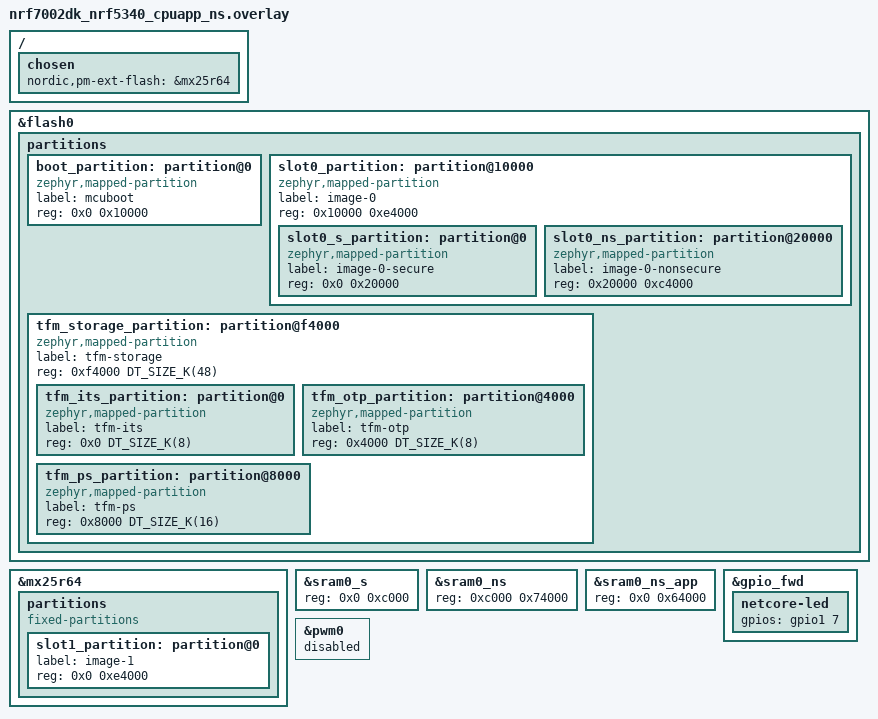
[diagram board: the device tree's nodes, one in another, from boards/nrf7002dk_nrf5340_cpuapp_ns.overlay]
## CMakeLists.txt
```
#
# Cranium firmware: application-core image (TF-M + non-secure application).
#
# Based on the nRF Connect SDK v3.4.0 sample samples/net/aws_iot
# (Copyright (c) 2020 Nordic Semiconductor ASA, LicenseRef-Nordic-5-Clause).
#

cmake_minimum_required(VERSION 3.20.0)

find_package(Zephyr REQUIRED HINTS $ENV{ZEPHYR_BASE})
project(cranium_app)

target_sources(app PRIVATE
  src/main.c
  src/cloud.c
  src/device.c
  src/factory.c
  src/health.c
  src/identity.c
  src/join_policy.c
  src/net.c
  src/ota.c
  src/ota_job.c
  src/store.c
  src/stuck.c
  src/stuck_policy.c
  src/ui.c
  src/version.c
)

target_sources_ifdef(CONFIG_APP_CONSOLE app PRIVATE
  src/console.c
  src/console_cmd.c
  src/console_keys.c
  src/console_parser.c
  src/console_stream.c
)

target_sources_ifdef(CONFIG_APP_BT_OTA app PRIVATE
  src/bt_ota.c
  src/bt_ota_policy.c
)

# MCUmgr's image header needs MCUboot's.
if(CONFIG_APP_BT_OTA)
  target_link_libraries(app PRIVATE MCUBOOT_BOOTUTIL)
endif()

# Only bt_ota.conf turns Bluetooth on. Without the console APP_BT_OTA stays off, which Kconfig only
# warns about, and this would be an image with a Bluetooth host and nobody to read a passkey.
if(CONFIG_BT AND NOT CONFIG_APP_BT_OTA)
  message(FATAL_ERROR "Firmware update over Bluetooth needs the console: CONFIG_APP_CONSOLE is off")
endif()

target_sources_ifndef(CONFIG_APP_CONSOLE app PRIVATE src/log_discard.c)

# The driver's recovery would power the chip back up, so the timer under test would never fire.
target_sources_ifdef(CONFIG_APP_TEST_FAULT_WIFI_DEAD app PRIVATE src/fault_wifi.c)
target_sources_ifdef(CONFIG_APP_BOOT_DIARY app PRIVATE src/boot_diary.c)
if(CONFIG_APP_TEST_FAULT_WIFI_DEAD AND CONFIG_NRF_WIFI_RPU_RECOVERY)
  message(FATAL_ERROR "APP_TEST_FAULT_WIFI_DEAD needs -Dapp_CONFIG_NRF_WIFI_RPU_RECOVERY=n as well")
endif()

zephyr_linker_sources_ifdef(CONFIG_LOG SECTIONS src/log_backend_check.ld)

target_include_directories(app PRIVATE src)
```

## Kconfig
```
#
# Cranium application settings.
#

menu "Cranium application"

config APP_THING_NAME_PREFIX
	string "Prefix of the AWS IoT thing name"
	default "cranium-"
	help
	  The thing name, which is also the MQTT client ID, is this prefix followed by
	  the SoC's factory-programmed device identifier.

config APP_DOWNLOAD_SEC_TAG
	int "TLS security tag for firmware downloads"
	default 202
	help
	  Holds only the root CA used to verify the download server. The device
	  certificate and private key are under CONFIG_MQTT_HELPER_SEC_TAG and are not
	  loaded for downloads.

config APP_SHADOW_INTERVAL_SECONDS
	int "Seconds between heartbeats: the periodic device shadow reports"
	default 30
	range 10 3600
	help
	  The console calls a board online if AWS IoT received one of these within the last
	  90 seconds (ONLINE_WINDOW_MS in cloud/api/src/lib/shadow.mjs). There is no second
	  message for this and no last will: this report is the heartbeat.

config APP_CLOUD_RETRY_SECONDS
	int "Seconds to wait before the first retry of a failed cloud connection"
	default 30
	range 5 600
	help
	  The wait doubles after every failure, up to five minutes.

config APP_WATCHDOG_TIMEOUT_SECONDS
	int "Hardware watchdog timeout"
	default 120
	range 30 600
	help
	  The main event loop feeds the watchdog. If the loop stops, the device resets,
	  and an update that has not been confirmed yet is reverted by the bootloader.

config APP_OTA_REQUIRE_USER_CONSENT
	bool "Wait for a button press before installing an update"
	default n
	help
	  Off: an update that passed every check starts as soon as the board sees the job,
	  with nobody at the board. The signature check, the version check, the trial and
	  the revert hold either way.

	  On, for a product that wants a person to agree: such an update is only offered. It
	  is downloaded and installed after Button 1 is pressed, and refused if Button 2 is
	  pressed. Firmware before 1.7.2 was built this way, and that includes the golden image.

config APP_OTA_SELF_TEST_TIMEOUT_SECONDS
	int "Seconds a new image has to prove itself"
	default 300
	range 60 3600
	help
	  A newly installed image runs on trial. If it has not reconnected to the cloud
	  within this time, the device resets and the bootloader restores the previous
	  image.

config APP_OTA_DOWNLOAD_ATTEMPTS
	int "Download attempts per update before it is reported as failed"
	default 5
	range 1 10
	help
	  The wait before another attempt grows with each one: 10 s, 20 s, 30 s and 40 s
	  with the default, so that an update survives a short outage of the network.

config APP_CONSOLE
	bool "Serial console for setup and debugging"
	depends on SERIAL && LOG
	default y
	select UART_INTERRUPT_DRIVEN
	select RING_BUFFER
	select BASE64
	select SYS_HEAP_RUNTIME_STATS
	help
	  One command per line on uart0: set the device ID, the Wi-Fi network and the
	  cloud settings, load the device credentials, check the status and reset the
	  board, without a host application or a reflash. Log messages come out here as
	  well. For development and provisioning builds only; a release build turns this
	  off with -Dapp_CONFIG_APP_CONSOLE=n, and its log messages then go nowhere. Nothing
	  here can read a secret back out of the device.

if APP_CONSOLE

config APP_CONSOLE_STACK_SIZE
	int "Stack of the console task"
	default 6144
	help
	  Creating the device key and its signing request runs on this stack.

config APP_CONSOLE_THREAD_PRIORITY
	int "Priority of the console task"
	default 12
	help
	  Lower than everything that keeps the product running, and higher than the log
	  thread, so that a reply goes out before the log lines it caused.

config APP_CONSOLE_TX_BUFFER_SIZE
	int "Bytes of output that can wait to be sent"
	default 4096
	range 1024 16384
	help
	  The console task waits for room here. Other threads never do: their line is
	  dropped and counted when it does not fit.

config APP_CONSOLE_LOG_HOLD_SIZE
	int "Bytes of log lines that can wait for a reply to finish"
	default 1024
	range 256 4096
	help
	  They go out all at once, so this cannot be larger than the transmit buffer.

config APP_CONSOLE_RX_BUFFER_SIZE
	int "Bytes of input that can wait for the console task"
	default 512
	range 128 2048

endif # APP_CONSOLE

config APP_BT_OTA
	bool "Firmware update over Bluetooth LE"
	depends on APP_CONSOLE && BT
	help
	  MCUmgr over Bluetooth LE, writing the secondary slot. Off by default. Build with
	  -DSB_EXTRA_CONF_FILE=bt_ota_sysbuild.conf, which also puts the Bluetooth controller on
	  the network core: see firmware/README.md. It needs the console, which is the only way
	  a person can see the passkey.

if APP_BT_OTA

config APP_BT_OTA_WINDOW_SECONDS
	int "Seconds that Button 1 opens Bluetooth for"
	default 120
	range 30 600
	help
	  Advertising stops after this, or as soon as a phone has connected. An authenticated
	  link can run on past it, as long as something happens on it.

config APP_BT_OTA_TRIAL_MIN_SECONDS
	int "Seconds a new image must have run before a person can keep it"
	default 60
	range 30 APP_OTA_SELF_TEST_TIMEOUT_SECONDS
	help
	  An image installed over Bluetooth, on a board that cannot reach Wi-Fi, can be kept by
	  a person at the board: see firmware/README.md. This long first, so that an image that
	  falls over soon after it starts does not get kept, and Wi-Fi has its chance.

endif # APP_BT_OTA

config APP_VERSION_FROM_BUILD
	bool
	default y
	help
	  Take the firmware version from the VERSION file. Off only in host-side tests.

config APP_BOOT_DIARY
	bool "Keep a record of the last boots and send it to the shadow"
	depends on APP_CONSOLE
	default y
	help
	  For finding out over the cloud why a board reset, when nobody can read its serial
	  port. Eight entries: the version, why the boot before it ended, and how far it got.
	  It writes to storage up to four times each boot.

choice APP_TEST_FAULT
	prompt "Fault built into a test image"
	default APP_TEST_FAULT_NONE
	help
	  For testing the way back. An image with a fault is signed and installs like any
	  other, then misbehaves on trial, so the bootloader has to restore the previous
	  image, unless its help says otherwise. Build one with, for example,
	  -Dapp_CONFIG_APP_TEST_FAULT_HANG=y. Never in a release.

config APP_TEST_FAULT_NONE
	bool "No fault"

config APP_TEST_FAULT_NO_CONFIRM
	bool "Runs and reaches the cloud, but never confirms itself"

config APP_TEST_FAULT_HANG
	bool "The main loop hangs, so the watchdog fires"

config APP_TEST_FAULT_CRASH
	bool "A fatal error right after start"

config APP_TEST_FAULT_INIT_POWER_LOSS
	bool "INIT restarts just before it writes the init-complete flag"
	depends on APP_CONSOLE
	help
	  A power cut at the worst moment of first-time setup, for
	  firmware/tests/hil/console_bench.py.

config APP_TEST_FAULT_WIFI_DEAD
	bool "A console command stops the Wi-Fi chip's power, once"
	depends on APP_CONSOLE
	help
	  Nothing happens until TEST_WIFI_DEAD is sent, so this image passes its trial and is
	  confirmed like any other. The command drives BUCKEN low and leaves IOVDD on, and from
	  then on the chip answers nothing. A restart brings it back. Build it with
	  -Dapp_CONFIG_NRF_WIFI_RPU_RECOVERY=n as well, or the driver powers the chip up again
	  and the timers in src/stuck.c never fire. For the chip-dead scenario of
	  firmware/tests/hil/ota_bench.py.

	  With APP_TEST_WIFI_DEAD_AFTER_SECONDS it also fires by itself, for a board with no
	  console: chip-dead-cloud in the same file.

config APP_TEST_FAULT_WRECK_SLOTS
	bool "Damages both image slots and restarts"
	help
	  Clears a word of the primary slot's hash and the first word of the secondary slot,
	  as a compromised application could. MCUboot then has no valid image, and the golden
	  image is the way back, for firmware/tests/hil/golden_bench.py.

config APP_TEST_FAULT_GOLDEN_FLIP
	bool "Damages the golden image in external flash, and runs on"
	help
	  Clears one bit of the golden copy at APP_TEST_GOLDEN_FLIP_OFFSET, through the flash
	  device, since this application's flash map has no area for it. A restore has to refuse
	  it whether the bit is in the image or in its signature, for
	  firmware/tests/hil/golden_bench.py.

endchoice

config APP_TEST_WIFI_DEAD_AFTER_SECONDS
	int "Seconds after its confirmation that the fault fires by itself"
	depends on APP_TEST_FAULT_WIFI_DEAD
	default 0
	range 0 3600
	help
	  0: only TEST_WIFI_DEAD does it. Otherwise it fires this long after the image was
	  confirmed, counted while no update is under way and the cloud is connected, and once
	  per install: the version it fired on is kept in storage, so it does not fire again
	  after the restart it causes. An image that got here with no swap has no trailer, so a
	  revert could not show, and there it does not fire. Build it with KIND set, as in
	  KIND=wifi-dead-auto firmware/tests/hil/build_image.sh, so that its build directory is
	  not the one of the image that waits for the command.

config APP_TEST_GOLDEN_FLIP_OFFSET
	int "Offset in the golden image of the byte that loses a bit"
	depends on APP_TEST_FAULT_GOLDEN_FLIP
	default 0
	range 0 933887
	help
	  `tools/golden.py offsets` gives one in the image's body and one in its signature.

module = APP
module-str = Cranium application
source "subsys/logging/Kconfig.template.log_config"

endmenu

menu "Zephyr Kernel"
source "Kconfig.zephyr"
endmenu
```

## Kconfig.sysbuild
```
#
# Sysbuild configuration: which images are built next to the application.
#

# MCUboot is always part of the build: nothing runs unless it verified the signature.
choice BOOTLOADER
	default BOOTLOADER_MCUBOOT
endchoice

# Without this sysbuild forces the nRF70 Wi-Fi driver off in the application image.
config WIFI_NRF70
	default y

# Flash and RAM layout come from the devicetree overlays in boards/.
config PARTITION_MANAGER
	default n

# The nRF5340 network core runs this project's own image instead of a radio stack.
config SUPPORT_NETCORE_BLINKY
	bool
	default y if SOC_SERIES_NRF53

choice NETCORE

config NETCORE_BLINKY
	bool "Cranium base-function image (LED heartbeat)"
	depends on SUPPORT_NETCORE_BLINKY
	help
	  Build firmware/netcore as the network-core image. It has no radio stack,
	  no keys and no console; it only toggles an LED.

endchoice

config NETCORE_IMAGE_NAME
	default "netcore_blinky" if NETCORE_BLINKY

config NETCORE_IMAGE_PATH
	default "$(APP_DIR)/../netcore" if NETCORE_BLINKY

# Firmware update over Bluetooth LE. Off unless bt_ota_sysbuild.conf is given: see there.
config APP_BT_OTA
	bool "Firmware update over Bluetooth LE"
	help
	  Adds src/bt_ota.c and the Bluetooth host to the application, through bt_ota.conf. The
	  network core has to run the Bluetooth controller, so bt_ota_sysbuild.conf selects that
	  too, and it has to be flashed over the debug port.

source "share/sysbuild/Kconfig"
```

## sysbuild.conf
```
#
# Sysbuild settings shared by every image.
#

SB_CONFIG_BOOTLOADER_MCUBOOT=y
SB_CONFIG_PARTITION_MANAGER=n
SB_CONFIG_WIFI_NRF70=y

# Images are signed with this project's own ECDSA P-256 key. The private key is kept
# outside the repository, in the home directory of whoever builds a release: create it
# with `python tools/keys.py generate` (or obtain the team key). Without this option
# the build would fall back to MCUboot's published debug key, which anyone can sign with.
SB_CONFIG_BOOT_SIGNATURE_TYPE_ECDSA_P256=y
SB_CONFIG_BOOT_SIGNATURE_KEY_FILE="\$ENV{HOME}/.cranium/mcuboot_signing_key.pem"

# Swap with revert: a new image runs once in "test" state and the bootloader puts the
# previous image back unless the application confirms it.
SB_CONFIG_MCUBOOT_MODE_SWAP_USING_MOVE=y

# Network core: base-function image, flashed over SWD only (not part of OTA).
SB_CONFIG_NETCORE_BLINKY=y
```

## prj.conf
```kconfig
#
# Cranium application-core image: settings that do not depend on the board.
# Board specifics (Wi-Fi, TF-M, bootloader, flash) are in boards/.
#
# Based on nRF Connect SDK v3.4.0 samples/net/aws_iot/prj.conf
# (Copyright (c) 2020 Nordic Semiconductor ASA, LicenseRef-Nordic-5-Clause).
#

# Diagnostics
CONFIG_LOG=y
CONFIG_ASSERT=y
CONFIG_REBOOT=y
CONFIG_HW_ID_LIBRARY=y

# Heap and stacks (the board file raises these for Wi-Fi and TLS)
CONFIG_HEAP_MEM_POOL_SIZE=8192
CONFIG_MAIN_STACK_SIZE=4096
CONFIG_SYSTEM_WORKQUEUE_STACK_SIZE=2048

# Network
CONFIG_NETWORKING=y
CONFIG_NET_NATIVE=y
CONFIG_NET_IPV4=y
CONFIG_NET_CONNECTION_MANAGER=y
# The driver's Kconfig sets 16 only along with its recovery, and the default is 5. Named here so that
# a fault image built without the recovery has the same queue as every other image.
CONFIG_NET_MGMT_EVENT_QUEUE_SIZE=16

# AWS IoT. The endpoint and the thing name are provisioned per device at run time and
# kept in secure storage, so no account-specific value is built into the image.
CONFIG_AWS_IOT=y
CONFIG_AWS_IOT_AUTO_DEVICE_SHADOW_REQUEST=n

# MQTT over TLS only (port 8883). Credentials live under this security tag.
CONFIG_MQTT_HELPER=y
CONFIG_MQTT_HELPER_SEC_TAG=201
CONFIG_MQTT_HELPER_STACK_SIZE=4096
CONFIG_MQTT_HELPER_PAYLOAD_BUFFER_LEN=4096
CONFIG_MQTT_HELPER_RX_TX_BUFFER_SIZE=512
CONFIG_MQTT_KEEPALIVE=120
CONFIG_MQTT_CLEAN_SESSION=y
# No last-will message: the device policy in AWS IoT allows publishing to the device's
# own shadow and jobs topics only, and a connection that announces any other topic is
# refused.
CONFIG_MQTT_HELPER_LAST_WILL=n

# Never compile certificates or keys into the firmware. With this option on, the device
# private key would be part of every OTA image stored in the cloud.
CONFIG_MQTT_HELPER_PROVISION_CERTIFICATES=n

# JSON parsing of job documents
CONFIG_CJSON_LIB=y

# Buttons (update confirmation, factory reset) and the hardware watchdog
CONFIG_INPUT=y
CONFIG_WATCHDOG=y

# Firmware download over HTTPS into the secondary slot. The application drives this
# itself instead of using the aws_fota library, which starts downloading without
# asking, reports success before the new image has run, and checks neither the
# version nor a digest.
CONFIG_AWS_FOTA=n
CONFIG_FOTA_DOWNLOAD=y
CONFIG_FOTA_DOWNLOAD_PROGRESS_EVT=y
CONFIG_FOTA_CLIENT_AUTOSCHEDULE_UPDATE=n
CONFIG_FOTA_DOWNLOAD_BUF_SZ=4096
CONFIG_DFU_TARGET=y
CONFIG_DFU_TARGET_MCUBOOT=y
CONFIG_DOWNLOADER=y
CONFIG_DOWNLOADER_STACK_SIZE=4096
# Presigned download URLs are long.
CONFIG_DOWNLOADER_MAX_FILENAME_SIZE=2048
# Never follow a redirect: it could lead to another host or to plain HTTP.
CONFIG_DOWNLOADER_MAX_REDIRECTS=0

# ---------------------------------------------------------------------------------
# Development and provisioning build: the serial console (src/console.h). A release
# build turns it off with -Dapp_CONFIG_APP_CONSOLE=n.
# ---------------------------------------------------------------------------------
CONFIG_APP_CONSOLE=y
# The console owns uart0, and logs go through it. Nothing else may print there. The
# second line overrides what the board's defaults say.
CONFIG_CONSOLE=n
CONFIG_UART_CONSOLE=n

# On-device key generation and certificate signing request
CONFIG_MBEDTLS_X509_CREATE_C=y
CONFIG_MBEDTLS_X509_CSR_WRITE_C=y
CONFIG_PSA_WANT_KEY_TYPE_ECC_KEY_PAIR_GENERATE=y
CONFIG_PSA_WANT_KEY_TYPE_ECC_KEY_PAIR_EXPORT=y
CONFIG_PSA_WANT_KEY_TYPE_ECC_KEY_PAIR_IMPORT=y
```

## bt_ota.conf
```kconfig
#
# What the application core needs for firmware updates over Bluetooth LE. Applied by
# sysbuild.cmake when SB_CONFIG_APP_BT_OTA is on. See bt_ota_sysbuild.conf.
#

CONFIG_APP_BT_OTA=y

# These sizes are not measured on a board yet. See "Before relying on it" in firmware/README.md.
# The Bluetooth stack asks for 4096 bytes more of heap, which CONFIG_HEAP_MEM_POOL_IGNORE_MIN drops
# in this project, and the IPC with the network core takes its queues from there at the first
# press. This keeps what Wi-Fi and TLS have free as it is without Bluetooth.
CONFIG_HEAP_MEM_POOL_SIZE=44240

# One peripheral link and nothing else: no scanning, no central role, no bonds in flash.
CONFIG_BT=y
CONFIG_BT_PERIPHERAL=y
CONFIG_BT_MAX_CONN=1
CONFIG_BT_DEVICE_NAME="Cranium"
CONFIG_BT_GATT_CACHING=n
CONFIG_BT_GATT_SERVICE_CHANGED=n

# On the air only as a resolvable private address, and a new one every 15 minutes. Nothing ever
# gets the key to resolve it, because nothing bonds.
CONFIG_BT_PRIVACY=y

# LE Secure Connections with MITM protection and a full-length key, or no pairing at all.
# A pairing lasts as long as the link: nothing is kept, so no phone can come back later.
CONFIG_BT_SMP=y
CONFIG_BT_SMP_SC_ONLY=y
CONFIG_BT_SMP_APP_PAIRING_ACCEPT=y
CONFIG_BT_BONDABLE=n
CONFIG_BT_SETTINGS=n

# Pairing runs on this thread. The default is for applications that do little, and nothing has
# measured how much this takes on a board yet.
CONFIG_BT_RX_STACK_SIZE=2048

# Room for one SMP packet in one ATT write, as in Zephyr's smp_svr sample.
CONFIG_BT_L2CAP_TX_MTU=498
CONFIG_BT_BUF_ACL_RX_SIZE=502
CONFIG_BT_BUF_ACL_TX_SIZE=502

# MCUmgr, with the image group only: there is no way to reset the board, read a file or run
# a shell from a phone. The permission is the first lock on the characteristic, and the
# hooks in src/bt_ota.c are the second.
CONFIG_NET_BUF=y
CONFIG_ZCBOR=y
CONFIG_CRC=y
CONFIG_MCUMGR=y
CONFIG_MCUMGR_TRANSPORT_BT=y
CONFIG_MCUMGR_TRANSPORT_BT_PERM_RW_AUTHEN=y
CONFIG_MCUMGR_TRANSPORT_NETBUF_SIZE=512
CONFIG_MCUMGR_TRANSPORT_NETBUF_COUNT=4
# As in smp_svr's bt.conf: the upload runs on it, down to the flash driver, and so do the hooks.
CONFIG_MCUMGR_TRANSPORT_WORKQUEUE_STACK_SIZE=4608
CONFIG_MCUMGR_GRP_IMG=y
CONFIG_MCUMGR_GRP_IMG_MUTEX=y
CONFIG_MCUMGR_GRP_IMG_UPLOAD_CHECK_HOOK=y
CONFIG_MCUMGR_GRP_IMG_STATUS_HOOKS=y
CONFIG_MCUMGR_MGMT_NOTIFICATION_HOOKS=y
CONFIG_MCUMGR_SMP_COMMAND_STATUS_HOOKS=y

# Never a permanent swap from a command, which would have no revert.
CONFIG_MCUMGR_GRP_IMG_ALLOW_CONFIRM_NON_ACTIVE_SLOT=n
CONFIG_MCUMGR_GRP_IMG_ALLOW_ERASE_PENDING=n
```

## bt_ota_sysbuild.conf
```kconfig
#
# The one switch for firmware updates over Bluetooth LE. Off in a normal build:
#
#   west build -b nrf7002dk/nrf5340/cpuapp/ns --sysbuild firmware/app -- -DSB_EXTRA_CONF_FILE=bt_ota_sysbuild.conf
#
# See "Firmware update over Bluetooth" in firmware/README.md. It takes a debug-port flash of
# the network core, and only then does an image built with it work.
#

SB_CONFIG_APP_BT_OTA=y

# The network core runs the Bluetooth controller instead of the blinky.
SB_CONFIG_NETCORE_HCI_IPC=y
```

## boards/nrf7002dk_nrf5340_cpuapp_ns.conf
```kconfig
#
# nRF7002 DK, application core, non-secure target (TF-M in the secure domain).
#
# Based on nRF Connect SDK v3.4.0
# samples/net/aws_iot/boards/nrf7002dk_nrf5340_cpuapp_ns.conf
# (Copyright (c) 2023 Nordic Semiconductor ASA, LicenseRef-Nordic-5-Clause).
#

# General
CONFIG_POSIX_TIMERS=y
CONFIG_SYSTEM_WORKQUEUE_STACK_SIZE=4096
CONFIG_HEAP_MEM_POOL_SIZE=40144
CONFIG_NRF_WIFI_CTRL_HEAP_SIZE=20000
CONFIG_NRF_WIFI_DATA_HEAP_SIZE=59856
CONFIG_HEAP_MEM_POOL_IGNORE_MIN=y
CONFIG_HW_STACK_PROTECTION=y
# Device identity: the SoC's factory-programmed 64-bit identifier
CONFIG_HWINFO=y
CONFIG_HW_ID_LIBRARY_SOURCE_DEVICE_ID=y
CONFIG_MAIN_STACK_SIZE=6144

# Optimize the Wi-Fi stack to save memory
CONFIG_NRF70_RX_NUM_BUFS=16
CONFIG_NRF70_MAX_TX_AGGREGATION=4

# Wi-Fi station. Credentials are stored through PSA in TF-M's internal trusted storage.
CONFIG_WIFI=y
CONFIG_WIFI_NRF70=y
CONFIG_WIFI_CREDENTIALS=y
CONFIG_WIFI_NM_WPA_SUPPLICANT=y
CONFIG_FLASH=y
CONFIG_FLASH_PAGE_LAYOUT=y
CONFIG_FLASH_MAP=y

# WEP and WPA (TKIP) are broken. Remove them, and the MD5/RC4 code they need, from
# the supplicant so that they cannot be negotiated at all.
CONFIG_WIFI_NM_WPA_SUPPLICANT_WEP=n
CONFIG_WIFI_NM_WPA_SUPPLICANT_LEGACY_CRYPTO=n

# Sockets
CONFIG_NET_L2_ETHERNET=y
CONFIG_NET_UDP=y
CONFIG_NET_TCP=y
CONFIG_NET_SOCKETS_OFFLOAD=n
CONFIG_NET_DHCPV4=y
CONFIG_NET_CONTEXT_SNDTIMEO=y
CONFIG_NET_CONTEXT_RCVTIMEO=y
CONFIG_NET_RX_STACK_SIZE=2048

# DNS
CONFIG_DNS_RESOLVER=y
CONFIG_NET_SOCKETS_DNS_TIMEOUT=30000

# TLS (Mbed TLS on PSA crypto; the crypto itself runs inside TF-M)
CONFIG_MBEDTLS=y
CONFIG_MBEDTLS_ENABLE_HEAP=y
CONFIG_MBEDTLS_HEAP_SIZE=81920
CONFIG_MBEDTLS_DECLARE_PRIVATE_IDENTIFIERS=y
CONFIG_MBEDTLS_MD_C=y
CONFIG_MBEDTLS_HMAC_DRBG_C=y
CONFIG_MBEDTLS_SHA256_C=y
CONFIG_MBEDTLS_ECP_C=y
CONFIG_MBEDTLS_RSA_C=y
CONFIG_PSA_WANT_KEY_TYPE_RSA_KEY_PAIR_IMPORT=y
CONFIG_PSA_WANT_KEY_TYPE_RSA_KEY_PAIR_EXPORT=y
CONFIG_PSA_WANT_KEY_TYPE_RSA_KEY_PAIR_GENERATE=y
CONFIG_MBEDTLS_SSL_SERVER_NAME_INDICATION=y
# 512-byte MPI limit so that 4096-bit RSA certificate chains can be verified.
CONFIG_MBEDTLS_MPI_MAX_SIZE=512
# ECDHE key agreement and ECDSA are needed for the TLS handshake
CONFIG_PSA_WANT_ALG_ECDH=y
CONFIG_PSA_WANT_ALG_ECDSA=y

CONFIG_NET_SOCKETS_SOCKOPT_TLS=y
# One TLS session for MQTT and one for the HTTPS firmware download, at the same time: the
# connection to AWS IoT stays up during a download, so that a cancellation still arrives.
CONFIG_NET_SOCKETS_TLS_MAX_CONTEXTS=2
# Each session takes its two record buffers from the heap above. What comes in must fit
# 16 KB, because neither S3 nor AWS IoT can be asked to send shorter records. What goes
# out is small: a request for the image, MQTT messages and one client certificate. With
# 16 KB in both directions the second session ran out of heap in the middle of the
# handshake, which Mbed TLS reports as -141 from mbedtls_x509_crt_parse_der().
CONFIG_MBEDTLS_SSL_OUT_CONTENT_LEN=4096

# The device certificate, its private key and the root CA are kept in TF-M Protected
# Storage (encrypted with a key derived from the hardware unique key), not in the image.
CONFIG_TLS_CREDENTIALS_BACKEND_PROTECTED_STORAGE=y

# Connection manager: the application decides when to connect.
CONFIG_L2_WIFI_CONNECTIVITY=y
CONFIG_L2_WIFI_CONNECTIVITY_AUTO_CONNECT=n
CONFIG_L2_WIFI_CONNECTIVITY_AUTO_DOWN=n

# External flash (MX25R64 on SPI) holds the secondary image slot. Use 4 KiB erase
# blocks in the application as well as in the bootloader so that erasing never
# reaches past the end of the slot.
CONFIG_SPI=y
CONFIG_SPI_NOR=y
CONFIG_SPI_NOR_SFDP_DEVICETREE=y
CONFIG_SPI_NOR_FLASH_LAYOUT_PAGE_SIZE=4096

# Bootloader support in the application
CONFIG_BOOTLOADER_MCUBOOT=y
CONFIG_MCUBOOT_USE_ALL_AVAILABLE_RAM=y
CONFIG_MCUBOOT_IMG_MANAGER=y
CONFIG_IMG_MANAGER=y
CONFIG_STREAM_FLASH=y
CONFIG_IMG_ERASE_PROGRESSIVELY=y
# MCUboot is built with downgrade prevention.
CONFIG_MCUBOOT_BOOTLOADER_NO_DOWNGRADE=y

# TF-M
CONFIG_TFM_PROFILE_TYPE_SMALL=y

# Network core: release it from reset. The RTC synchronisation service between the
# cores is not needed because the two images do not talk to each other.
CONFIG_SOC_NRF53_CPUNET_ENABLE=y
CONFIG_NRF53_SYNC_RTC=n

# Link-time optimisation is needed to fit the non-secure image
CONFIG_LTO=y
CONFIG_ISR_TABLES_LOCAL_DECLARATION=y

CONFIG_CBPRINTF_FP_SUPPORT=y
```

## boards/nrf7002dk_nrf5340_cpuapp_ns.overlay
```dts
/*
 * nRF7002 DK application core: flash and RAM layout, external flash, and the pins
 * handed to the network core.
 *
 * Based on nRF Connect SDK v3.4.0
 * samples/net/aws_iot/boards/nrf7002dk_nrf5340_cpuapp_ns.overlay
 * (Copyright (c) 2023 Nordic Semiconductor ASA, LicenseRef-Nordic-5-Clause).
 */

/ {
	chosen {
		/*
		 * Tells the build that the secondary image slot is on external flash.
		 * Needed even though Partition Manager is not used.
		 */
		nordic,pm-ext-flash = &mx25r64;
	};
};

/delete-node/ &boot_partition;
/delete-node/ &slot0_partition;
/delete-node/ &slot1_partition;
/delete-node/ &tfm_its_partition;
/delete-node/ &tfm_otp_partition;
/delete-node/ &tfm_ps_partition;
/delete-node/ &storage_partition;

/*
 * Internal flash (1 MiB):
 *
 *   0x00000  64 KiB   MCUboot (write-protected once it has started the application)
 *   0x10000 912 KiB   primary image slot
 *             128 KiB   TF-M, secure
 *             784 KiB   application, non-secure
 *   0xf4000  48 KiB   TF-M storage: internal trusted storage, NV counters, protected storage
 */
&flash0 {
	partitions {
		boot_partition: partition@0 {
			compatible = "zephyr,mapped-partition";
			label = "mcuboot";
			reg = <0x0 0x10000>;
		};

		slot0_partition: partition@10000 {
			compatible = "zephyr,mapped-partition";
			label = "image-0";
			reg = <0x10000 0xe4000>;
			ranges = <0x0 0x10000 0xe4000>;
			#address-cells = <1>;
			#size-cells = <1>;

			slot0_s_partition: partition@0 {
				compatible = "zephyr,mapped-partition";
				label = "image-0-secure";
				reg = <0x0 0x20000>;
			};

			slot0_ns_partition: partition@20000 {
				compatible = "zephyr,mapped-partition";
				label = "image-0-nonsecure";
				reg = <0x20000 0xc4000>;
			};
		};

		tfm_storage_partition: partition@f4000 {
			compatible = "zephyr,mapped-partition";
			label = "tfm-storage";
			reg = <0xf4000 DT_SIZE_K(48)>;
			ranges = <0x0 0xf4000 DT_SIZE_K(48)>;
			#address-cells = <1>;
			#size-cells = <1>;

			tfm_its_partition: partition@0 {
				compatible = "zephyr,mapped-partition";
				label = "tfm-its";
				reg = <0x0 DT_SIZE_K(8)>;
			};

			tfm_otp_partition: partition@4000 {
				compatible = "zephyr,mapped-partition";
				label = "tfm-otp";
				reg = <0x4000 DT_SIZE_K(8)>;
			};

			tfm_ps_partition: partition@8000 {
				compatible = "zephyr,mapped-partition";
				label = "tfm-ps";
				reg = <0x8000 DT_SIZE_K(16)>;
			};
		};
	};
};

/*
 * External flash: the secondary image slot, the same size as the primary slot.
 *
 * 0x700000 to 0x7e4000 is reserved for the golden image. MCUboot's overlay declares that
 * partition, and this one does not on purpose, so that this application's flash map has no
 * area for it. Keep it out of anything added here. See firmware/README.md.
 */
&mx25r64 {
	status = "okay";

	partitions {
		compatible = "fixed-partitions";
		#address-cells = <1>;
		#size-cells = <1>;

		slot1_partition: partition@0 {
			label = "image-1";
			reg = <0x0 0xe4000>;
		};
	};
};

/*
 * RAM split between the secure and the non-secure domain. TF-M gets 48 KiB at the base
 * of the application-core SRAM; the non-secure window is 0x74000 bytes, of which the
 * top 64 KiB is the memory the two cores can share.
 */
&sram0_s {
	reg = <0x0 0xc000>;
};

&sram0_ns {
	reg = <0xc000 0x74000>;
	ranges = <0x0 0xc000 0x74000>;
};

&sram0_ns_app {
	reg = <0x0 0x64000>;
};

/*
 * Pins owned by the network core. By default the board forwards the network core's
 * UART pins; this image has no console, so only LED2 (P1.07) is handed over. LED1 and
 * both buttons stay with the application core.
 */
&gpio_fwd {
	/delete-node/ uart;

	netcore-led {
		gpios = <&gpio1 7 0>;
	};
};

/* LED1 (P1.06) is driven as a plain GPIO, so release it from the PWM peripheral. */
&pwm0 {
	status = "disabled";
};
```

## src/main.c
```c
/*
 * Cranium firmware, application core: the security domain of the product.
 *
 * This is the non-secure application that runs on top of Trusted Firmware-M. It joins
 * Wi-Fi, keeps an authenticated connection to AWS IoT, reports the device's state and
 * installs firmware updates. Everything is driven by one event loop.
 */

#include <string.h>

#include <cJSON_os.h>
#include <zephyr/kernel.h>
#include <zephyr/logging/log.h>
#include <zephyr/logging/log_ctrl.h>
#include <zephyr/sys/atomic.h>
#include <zephyr/sys/reboot.h>

#include "app_events.h"
#if defined(CONFIG_APP_BT_OTA)
#include "bt_ota.h"
#endif
#include "cloud.h"
#include "console.h"
#include "device.h"
#if defined(CONFIG_APP_TEST_FAULT_WIFI_DEAD)
#include "fault_wifi.h"
#endif
#if defined(CONFIG_APP_BOOT_DIARY)
#include "boot_diary.h"
#endif
#include "identity.h"
#include "factory.h"
#include "health.h"
#include "net.h"
#include "ota.h"
#include "ota_job.h"
#include "stuck.h"
#include "ui.h"
#include "version.h"

#if defined(CONFIG_APP_TEST_FAULT_WRECK_SLOTS)
#include <zephyr/storage/flash_map.h>
#include <zephyr/sys/util.h>
#endif

#if defined(CONFIG_APP_TEST_FAULT_GOLDEN_FLIP)
#include <zephyr/device.h>
#include <zephyr/devicetree.h>
#include <zephyr/drivers/flash.h>
#endif

LOG_MODULE_REGISTER(app, CONFIG_APP_LOG_LEVEL);

#define CLOUD_SETTLE_SECONDS    3
#define CLOUD_BACKOFF_MAX       300

K_MSGQ_DEFINE(event_queue, sizeof(struct app_event), 32, 4);

static int cloud_retry_in = -1;
static int cloud_backoff = CONFIG_APP_CLOUD_RETRY_SECONDS;
/* Since the last report to the shadow. A report that nothing asked for is the board's heartbeat. */
static int seconds_since_report;
/* A tick is in the queue. A main loop that is held up must not come back to a queue full of them. */
static atomic_t tick_queued;

int app_event_post(const struct app_event *event)
{
	return k_msgq_put(&event_queue, event, K_NO_WAIT);
}

int app_event_post_simple(enum app_event_type type)
{
	const struct app_event event = { .type = type };

	return app_event_post(&event);
}

static void on_tick_timer(struct k_timer *timer)
{
	ARG_UNUSED(timer);

	/* Other events are lost if they find the queue full. What counts time goes by uptime. */
	if (atomic_cas(&tick_queued, 0, 1) && app_event_post_simple(APP_EVENT_TICK) != 0) {
		atomic_set(&tick_queued, 0);
	}
}

K_TIMER_DEFINE(tick_timer, on_tick_timer, NULL);

static bool provisioned(void)
{
	return identity_settings_get() != NULL && net_has_credentials();
}

static void update_ui(void)
{
#if defined(CONFIG_APP_BT_OTA)
	if (bt_ota_is_open()) {
		ui_set_state(bt_ota_ui_state());
		return;
	}
#endif

	switch (ota_state()) {
	case OTA_AWAITING_USER:
		ui_set_state(UI_UPDATE_OFFERED);
		return;
	case OTA_RETRY_WAIT:
	case OTA_REFRESHING:
	case OTA_STARTING:
	case OTA_DOWNLOADING:
	case OTA_VERIFYING:
	case OTA_COMMITTING:
	case OTA_REBOOTING:
		ui_set_state(UI_UPDATE_IN_PROGRESS);
		return;
	case OTA_TESTING:
		ui_set_state(UI_UPDATE_TESTING);
		return;
	default:
		break;
	}

	if (device_is_factory()) {
		ui_set_state(UI_FACTORY);
	} else if (!provisioned()) {
		ui_set_state(UI_UNPROVISIONED);
	} else if (!net_is_up()) {
		ui_set_state(UI_NETWORK_CONNECTING);
	} else if (!cloud_is_connected()) {
		ui_set_state(UI_CLOUD_CONNECTING);
	} else {
		ui_set_state(UI_ONLINE);
	}
}

/*
 * Publish what the console shows for this device. Nothing here is secret. AWS IoT stamps the time
 * that it gets the uptime, which is what the console calls the last heartbeat, and there is no other
 * message for that.
 */
static void publish_report(void)
{
	char job[OTA_JOB_ID_MAX + 3] = "null";
	char reported[400];
	const char *job_id = ota_job_id();
	int written;

	if (!cloud_is_connected()) {
		return;
	}

	if (job_id != NULL) {
		(void)snprintk(job, sizeof(job), "\"%s\"", job_id);
	}

	written = snprintk(reported, sizeof(reported),
			   "{\"fw\":{\"version\":\"%s\",\"confirmed\":%s},"
			   "\"ota\":{\"state\":\"%s\",\"job\":%s,\"progress\":%d,"
			   "\"last\":\"%s\",\"error\":\"%s\"},"
			   "\"wifi\":{\"rssi\":%d},\"stuck\":{\"count\":%u,\"reason\":\"%s\"},"
			   "\"uptime\":%lld}",
			   fw_version_running_string(),
			   ota_state() == OTA_TESTING ? "false" : "true", ota_state_name(), job,
			   ota_progress(), ota_last_result(), ota_last_error(), net_rssi(),
			   (unsigned int)stuck_count(), stuck_reason_name(),
			   k_uptime_get() / MSEC_PER_SEC);

	if (written > 0 && written < (int)sizeof(reported)) {
		(void)cloud_shadow_report(reported);
	}

	seconds_since_report = 0;
}

static void on_tick(void)
{
	health_feed();

	/* In factory mode the board stays off the network until INIT has been run. */
	if (!device_is_factory()) {
		net_tick();
	}

	if (net_is_up() && !cloud_is_connected() && identity_settings_get() != NULL) {
		/* The events that set this can be lost. Nobody would try again until the link drops. */
		if (cloud_retry_in < 0 && !cloud_is_connecting()) {
			cloud_retry_in = cloud_backoff;
		}

		if (cloud_retry_in >= 0 && --cloud_retry_in < 0) {
			cloud_connect();
		}
	}

	ota_on_tick();

#if defined(CONFIG_APP_TEST_FAULT_WIFI_DEAD)
	fault_wifi_on_tick();
#endif

#if defined(CONFIG_APP_BT_OTA)
	bt_ota_on_tick();
	update_ui();
#endif

	if (ota_take_changed()) {
		publish_report();
		update_ui();
	} else if (++seconds_since_report >= CONFIG_APP_SHADOW_INTERVAL_SECONDS) {
		publish_report();
	}

	stuck_on_tick();
}

static void on_button(const struct app_event *event)
{
#if defined(CONFIG_APP_BT_OTA)
	if (bt_ota_on_button(event->button.id, event->button.long_press, event->button.physical)) {
		return;
	}
#endif

	/* Holding Button 2 erases everything that was provisioned onto the device. */
	if (event->button.id == APP_BUTTON_2 && event->button.long_press) {
		if (ota_state() != OTA_IDLE) {
			LOG_WRN("Factory reset ignored while an update is in progress");
			return;
		}

		cloud_disconnect();
		(void)factory_reset();
		LOG_PANIC();
		sys_reboot(SYS_REBOOT_COLD);
	}

	ota_on_button(event->button.id);
}

static void on_job_message(void)
{
	enum cloud_job_message kind;
	const char *payload;
	size_t length;

	if (cloud_job_message_get(&kind, &payload, &length)) {
		ota_on_job_message(kind, payload, length);
	}

	if (cloud_job_message_done()) {
		/* Another jobs message arrived meanwhile and was dropped: ask again. */
		(void)cloud_jobs_request_next();
	}
}

static void decide_mode(void)
{
	switch (device_boot()) {
	case DEVICE_BOOT_MIGRATED:
		console_event("CONSOLE", "migrated: device id set to %s", device_id());
		break;
	case DEVICE_BOOT_MIGRATION_FAILED:
		LOG_ERR("The device id could not be stored; will try again at the next boot");
		break;
	case DEVICE_BOOT_UNREADABLE:
		LOG_ERR("Storage could not be read; running as provisioned, nothing was written");
		break;
	default:
		break;
	}
}

static void handle(const struct app_event *event)
{
	switch (event->type) {
	case APP_EVENT_NET_UP:
		LOG_INF("Network is up");
#if defined(CONFIG_APP_BOOT_DIARY)
		boot_diary_stage(BOOT_DIARY_NET_UP);
#endif
		net_report_up();
		cloud_retry_in = CLOUD_SETTLE_SECONDS;
		break;
	case APP_EVENT_NET_DOWN:
		LOG_INF("Network is down");
		net_report_down();
		cloud_disconnect();
		cloud_retry_in = -1;
		break;
	case APP_EVENT_NET_JOIN:
		stuck_on_new_settings();
		(void)net_connect();
		break;
	case APP_EVENT_NET_JOIN_FAILED:
		net_report_join_failed(event->join_failed.reason);
		break;
	case APP_EVENT_CLOUD_UP:
		LOG_INF("Connected to AWS IoT");
		cloud_backoff = CONFIG_APP_CLOUD_RETRY_SECONDS;
		cloud_retry_in = -1;
		ota_on_cloud_up();
		publish_report();
#if defined(CONFIG_APP_BOOT_DIARY)
		boot_diary_stage(BOOT_DIARY_CLOUD_UP);
		boot_diary_report();
#endif
		break;
	case APP_EVENT_CLOUD_DOWN:
		LOG_INF("Disconnected from AWS IoT");
		if (net_is_up()) {
			cloud_retry_in = cloud_backoff;
			cloud_backoff = MIN(cloud_backoff * 2, CLOUD_BACKOFF_MAX);
		}
		break;
	case APP_EVENT_CLOUD_CHANGED:
		stuck_on_new_settings();
		cloud_backoff = CONFIG_APP_CLOUD_RETRY_SECONDS;
		cloud_retry_in = CLOUD_SETTLE_SECONDS;
		break;
	case APP_EVENT_JOB_MESSAGE:
		on_job_message();
		break;
	case APP_EVENT_JOB_ACK:
		ota_on_job_ack(event->job_ack.kind, event->job_ack.sequence, event->job_ack.accepted,
			       event->job_ack.permanent);
		break;
	case APP_EVENT_BUTTON:
		on_button(event);
		break;
	case APP_EVENT_DOWNLOAD:
		ota_on_download(event->download.what, event->download.value);
		break;
	case APP_EVENT_TICK:
		atomic_set(&tick_queued, 0);
		on_tick();
		return;
	case APP_EVENT_CALL:
		event->call.function();
		break;
	default:
		break;
	}

	update_ui();
}

#if defined(CONFIG_APP_TEST_FAULT_WRECK_SLOTS)
/* Where an MCUboot image keeps its metadata. See bootutil/image.h in MCUboot. */
#define IMAGE_HEADER_HDR_SIZE_OFFSET 8
#define IMAGE_TLV_INFO_MAGIC         0x6907
#define IMAGE_TLV_SHA256             0x10

struct image_sizes {
	uint16_t header;
	uint16_t protected_tlv;
	uint32_t image;
};

struct image_tlv_entry {
	uint8_t type;
	uint8_t unused;
	uint16_t length;
};

struct image_tlv_area {
	uint16_t magic;
	uint16_t total;
};

/* Writing zeros needs no erase: that is why anything with write access can do this. */
static void clear_word(const struct flash_area *area, off_t offset)
{
	const uint32_t zero = 0;
	int err = flash_area_write(area, offset, &zero, sizeof(zero));

	LOG_ERR("Test image: cleared the word at %ld of area %u: %d", (long)offset, area->fa_id, err);
}

/* The offset of the first whole word of the image's hash, or -1 if it cannot be found. */
static off_t find_hash(const struct flash_area *area)
{
	struct image_sizes sizes;
	struct image_tlv_area tlvs;
	struct image_tlv_entry entry;
	off_t offset;
	off_t end;

	if (flash_area_read(area, IMAGE_HEADER_HDR_SIZE_OFFSET, &sizes, sizeof(sizes)) != 0) {
		return -1;
	}

	offset = (off_t)sizes.header + sizes.image + sizes.protected_tlv;
	if (flash_area_read(area, offset, &tlvs, sizeof(tlvs)) != 0 ||
	    tlvs.magic != IMAGE_TLV_INFO_MAGIC) {
		return -1;
	}

	end = offset + tlvs.total;
	offset += sizeof(tlvs);

	while (offset < end && flash_area_read(area, offset, &entry, sizeof(entry)) == 0) {
		offset += sizeof(entry);
		if (entry.type == IMAGE_TLV_SHA256) {
			return ROUND_UP(offset, sizeof(uint32_t));
		}
		offset += entry.length;
	}

	return -1;
}

/* What a compromised application could do to the way back. It runs once: then nothing is valid. */
static void wreck_slots(void)
{
	const struct flash_area *area;
	off_t hash;

	if (flash_area_open(PARTITION_ID(slot0_partition), &area) == 0) {
		hash = find_hash(area);
		if (hash >= 0) {
			clear_word(area, hash);
		} else {
			LOG_ERR("Test image: the primary slot's hash was not found");
		}
		flash_area_close(area);
	}

	if (flash_area_open(PARTITION_ID(slot1_partition), &area) == 0) {
		clear_word(area, 0);
		flash_area_close(area);
	}
}
#endif /* CONFIG_APP_TEST_FAULT_WRECK_SLOTS */

#if defined(CONFIG_APP_TEST_FAULT_GOLDEN_FLIP)
/* golden_partition in MCUboot's overlay. This application has no area for it, on purpose. */
#define GOLDEN_FLASH_ADDRESS 0x700000

/* Clear one set bit: writing zeros needs no erase. Each boot of this image clears one more. */
static void damage_golden_copy(void)
{
	const struct device *flash = DEVICE_DT_GET(DT_NODELABEL(mx25r64));
	const off_t address = GOLDEN_FLASH_ADDRESS + CONFIG_APP_TEST_GOLDEN_FLIP_OFFSET;
	uint8_t before;
	uint8_t after;
	int err = device_is_ready(flash) ? flash_read(flash, address, &before, 1) : -ENODEV;

	if (err == 0 && before == 0) {
		LOG_ERR("Test image: the golden byte at %ld has no bit left to clear", (long)address);
		return;
	}

	if (err == 0) {
		after = before & (before - 1);
		err = flash_write(flash, address, &after, 1);
	}

	if (err != 0) {
		LOG_ERR("Test image: the golden copy could not be damaged: %d", err);
		return;
	}

	LOG_ERR("Test image: golden byte at %ld changed from %02x to %02x", (long)address, before,
		after);
}
#endif /* CONFIG_APP_TEST_FAULT_GOLDEN_FLIP */

int main(void)
{
	struct app_event event;

	LOG_INF("Cranium firmware %s", fw_version_running_string());

#if defined(CONFIG_APP_BOOT_DIARY)
	boot_diary_begin();
#endif

	cJSON_Init();

	if (health_init() != 0) {
		LOG_WRN("Running without a watchdog");
	}

	(void)ui_init();

	if (identity_init() != 0) {
		LOG_ERR("Device identity is not available");
	}

	LOG_INF("Thing name: %s", identity_thing_name());

	decide_mode();
	console_start();
	stuck_init();

	if (ota_init() != 0) {
		LOG_ERR("Update manager could not start");
	}

#if defined(CONFIG_APP_BOOT_DIARY)
	boot_diary_stage(BOOT_DIARY_OTA_READY);
#endif

	if (net_init() != 0) {
		LOG_ERR("Networking could not start");
	}

	/*
	 * Whatever came of that. net_init() does not wait for the Wi-Fi stack, so this runs on a chip
	 * that did not come up as well. net_connect() tries the interface again from the tick, and
	 * the stuck timers restart the board if it stays that way.
	 */
	if (cloud_init() != 0) {
		LOG_ERR("The cloud connection could not start");
	}

	if (device_is_factory()) {
		LOG_WRN("Factory mode: send INIT|<id> on the console");
	} else if (net_has_credentials()) {
		(void)net_connect();
	}

	if (!device_is_factory() && !provisioned()) {
		LOG_WRN("This device is not provisioned yet (see tools/provision_device.py)");
	}

	update_ui();
	k_timer_start(&tick_timer, K_SECONDS(1), K_SECONDS(1));

	if (IS_ENABLED(CONFIG_APP_TEST_FAULT_CRASH)) {
		LOG_ERR("Test image: crashing on purpose");
		LOG_PANIC();
		k_oops();
	}

	if (IS_ENABLED(CONFIG_APP_TEST_FAULT_HANG)) {
		LOG_ERR("Test image: hanging on purpose, the watchdog will fire");
		while (true) {
			k_msleep(MSEC_PER_SEC);
		}
	}

#if defined(CONFIG_APP_TEST_FAULT_WRECK_SLOTS)
	LOG_ERR("Test image: damaging both image slots on purpose");
	wreck_slots();
	LOG_PANIC();
	sys_reboot(SYS_REBOOT_COLD);
#endif

#if defined(CONFIG_APP_TEST_FAULT_GOLDEN_FLIP)
	LOG_ERR("Test image: damaging the golden copy on purpose");
	damage_golden_copy();
#endif

	while (true) {
		(void)k_msgq_get(&event_queue, &event, K_FOREVER);
		handle(&event);
	}

	return 0;
}
```

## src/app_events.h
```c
/*
 * Events handled by the application's single event loop.
 *
 * Library callbacks run on several threads (MQTT, downloader, input, network
 * management), and the serial console has a task of its own. They only post one of
 * these events; every state change then happens on the main thread, one event at a time.
 */

#ifndef APP_EVENTS_H_
#define APP_EVENTS_H_

#include <stdbool.h>
#include <stdint.h>

enum app_event_type {
	APP_EVENT_NET_UP,
	APP_EVENT_NET_DOWN,
	/* Start joining the stored network. */
	APP_EVENT_NET_JOIN,
	/* An attempt to join did not work out. */
	APP_EVENT_NET_JOIN_FAILED,
	APP_EVENT_CLOUD_UP,
	APP_EVENT_CLOUD_DOWN,
	/* The cloud settings have changed: connect again soon, with the new ones. */
	APP_EVENT_CLOUD_CHANGED,
	/* A jobs message (the next job, or the reply to a request for it) is waiting. */
	APP_EVENT_JOB_MESSAGE,
	/* AWS IoT answered a job status update that the update logic is waiting on. */
	APP_EVENT_JOB_ACK,
	APP_EVENT_BUTTON,
	APP_EVENT_DOWNLOAD,
	/* Once a second. */
	APP_EVENT_TICK,
	/* Run a function here: how the console task reads and changes what this loop owns. */
	APP_EVENT_CALL,
};

enum app_button {
	APP_BUTTON_1,
	APP_BUTTON_2,
};

enum app_download_event {
	APP_DOWNLOAD_PROGRESS,
	APP_DOWNLOAD_FINISHED,
	APP_DOWNLOAD_ERROR,
	APP_DOWNLOAD_CANCELLED,
};

struct app_event {
	enum app_event_type type;
	union {
		struct {
			uint8_t id;
			bool long_press;
#if defined(CONFIG_APP_BT_OTA)
			/* A real press of a real button, not a command on the console. */
			bool physical;
#endif
		} button;
		struct {
			uint8_t what;
			/* Percent for progress, library error cause for an error. */
			int16_t value;
		} download;
		struct {
			/* Which update this answers: the token it was sent with. */
			char kind;
			uint16_t sequence;
			bool accepted;
			/* Rejected for a reason that sending it again cannot change. */
			bool permanent;
		} job_ack;
		struct {
			int16_t reason;
		} join_failed;
		struct {
			void (*function)(void);
		} call;
	};
};

/* Queue an event for the main loop. Safe from any thread and from interrupts. */
int app_event_post(const struct app_event *event);

/* Shorthand for events that carry no data. */
int app_event_post_simple(enum app_event_type type);

#endif /* APP_EVENTS_H_ */
```

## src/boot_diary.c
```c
#include "boot_diary.h"

#include <stdio.h>
#include <string.h>

#include <zephyr/kernel.h>
#include <zephyr/logging/log.h>
#include <zephyr/sys/util.h>

#include "cloud.h"
#include "console.h"
#include "store.h"
#include "version.h"

LOG_MODULE_REGISTER(boot_diary, CONFIG_APP_LOG_LEVEL);

#define ENTRIES 8
#define DIARY_MAGIC 0x44494152u

struct entry {
	char version[16];
	/* Why the boot before this one ended: Zephyr's hwinfo RESET_ bits. */
	uint32_t cause;
	uint8_t stage;
};

static struct {
	uint32_t magic;
	uint32_t boots;
	uint8_t next;
	struct entry entries[ENTRIES];
} diary;

static uint8_t current;

void boot_diary_begin(void)
{
	if (store_read(STORE_BOOT_DIARY, &diary, sizeof(diary)) != 0 || diary.magic != DIARY_MAGIC ||
	    diary.next >= ENTRIES) {
		memset(&diary, 0, sizeof(diary));
		diary.magic = DIARY_MAGIC;
	}

	current = diary.next;
	diary.next = (diary.next + 1) % ENTRIES;
	diary.boots++;
	strncpy(diary.entries[current].version, fw_version_running_string(),
		sizeof(diary.entries[current].version) - 1);
	diary.entries[current].version[sizeof(diary.entries[current].version) - 1] = '\0';
	diary.entries[current].cause = console_last_reset_cause();
	diary.entries[current].stage = BOOT_DIARY_MAIN;
	(void)store_write(STORE_BOOT_DIARY, &diary, sizeof(diary));
}

void boot_diary_stage(enum boot_diary_stage stage)
{
	if (diary.entries[current].stage < stage) {
		diary.entries[current].stage = stage;
		(void)store_write(STORE_BOOT_DIARY, &diary, sizeof(diary));
	}
}

void boot_diary_report(void)
{
	static char json[480];
	size_t used = 0;

	used += snprintf(json + used, sizeof(json) - used, "{\"diary\":{\"boots\":%u,\"log\":[",
			 diary.boots);
	/* Oldest first. */
	for (size_t i = 0; i < ENTRIES && used < sizeof(json); i++) {
		const struct entry *entry = &diary.entries[(diary.next + i) % ENTRIES];

		if (entry->version[0] == '\0') {
			continue;
		}
		used += snprintf(json + used, sizeof(json) - used, "%s\"%s/%x/%u\"",
				 json[used - 1] == '[' ? "" : ",", entry->version, entry->cause,
				 entry->stage);
	}
	if (used + 3 < sizeof(json)) {
		strcpy(json + used, "]}}");
		(void)cloud_shadow_report(json);
	}
}
```

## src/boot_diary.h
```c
/*
 * A record of the last boots, for finding out over the cloud why a board reset when nobody can
 * read its serial port. With CONFIG_APP_BOOT_DIARY. Each entry is version/cause/stage, where the
 * cause is why the boot before it ended, in Zephyr's hwinfo RESET_ bits.
 */

#ifndef BOOT_DIARY_H_
#define BOOT_DIARY_H_

enum boot_diary_stage {
	BOOT_DIARY_MAIN = 1,
	BOOT_DIARY_OTA_READY = 2,
	BOOT_DIARY_NET_UP = 3,
	BOOT_DIARY_CLOUD_UP = 4,
};

/* First thing in main(): a new entry, with why the last boot ended. */
void boot_diary_begin(void);

/* How far this boot has got. Each stage writes to storage, so a reset right after it still shows. */
void boot_diary_stage(enum boot_diary_stage stage);

/* Send the entries to the device shadow as "diary". */
void boot_diary_report(void);

#endif /* BOOT_DIARY_H_ */
```

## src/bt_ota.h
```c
/*
 * Firmware update over Bluetooth LE, behind CONFIG_APP_BT_OTA.
 *
 * Bluetooth is off until a person holds Button 1 for five seconds and lets go. That opens a
 * window of limited time: the board advertises, a phone connects and pairs with the passkey
 * that comes out on the console, and it can upload an image to the secondary slot over
 * MCUmgr. The image is then offered, as a cloud update is: Button 1 asks the bootloader for a
 * trial swap and restarts, and Button 2 erases it. The bootloader checks the signature, and the
 * image stays on trial. See "Firmware update over Bluetooth" in firmware/README.md.
 *
 * All functions run on the main loop, unless they say otherwise.
 */

#ifndef BT_OTA_H_
#define BT_OTA_H_

#include <stdbool.h>
#include <stdint.h>

#include "bt_ota_policy.h"
#include "ui.h"

/* Called by ota_init(), which knows what the bootloader did. job_record: see ota_bt_has_job(). */
void bt_ota_on_boot(bool on_trial, bool has_trailer, bool job_record);

/*
 * A button was let go. Returns true if that was for this module, and nothing else should act
 * on it. physical: a real press of a real button, which a command on the console is not.
 */
bool bt_ota_on_button(uint8_t button, bool long_press, bool physical);

void bt_ota_on_tick(void);

/* The image on trial has been confirmed because it reached the cloud. */
void bt_ota_on_cloud_proof(void);

/* Connected to the cloud: tell it about the last update over Bluetooth. */
void bt_ota_on_cloud_up(void);

bool bt_ota_is_open(void);
enum ui_state bt_ota_ui_state(void);

#endif /* BT_OTA_H_ */
```
